AUTOSAR XML (schema 4-0-3)
package /ComponentTypes
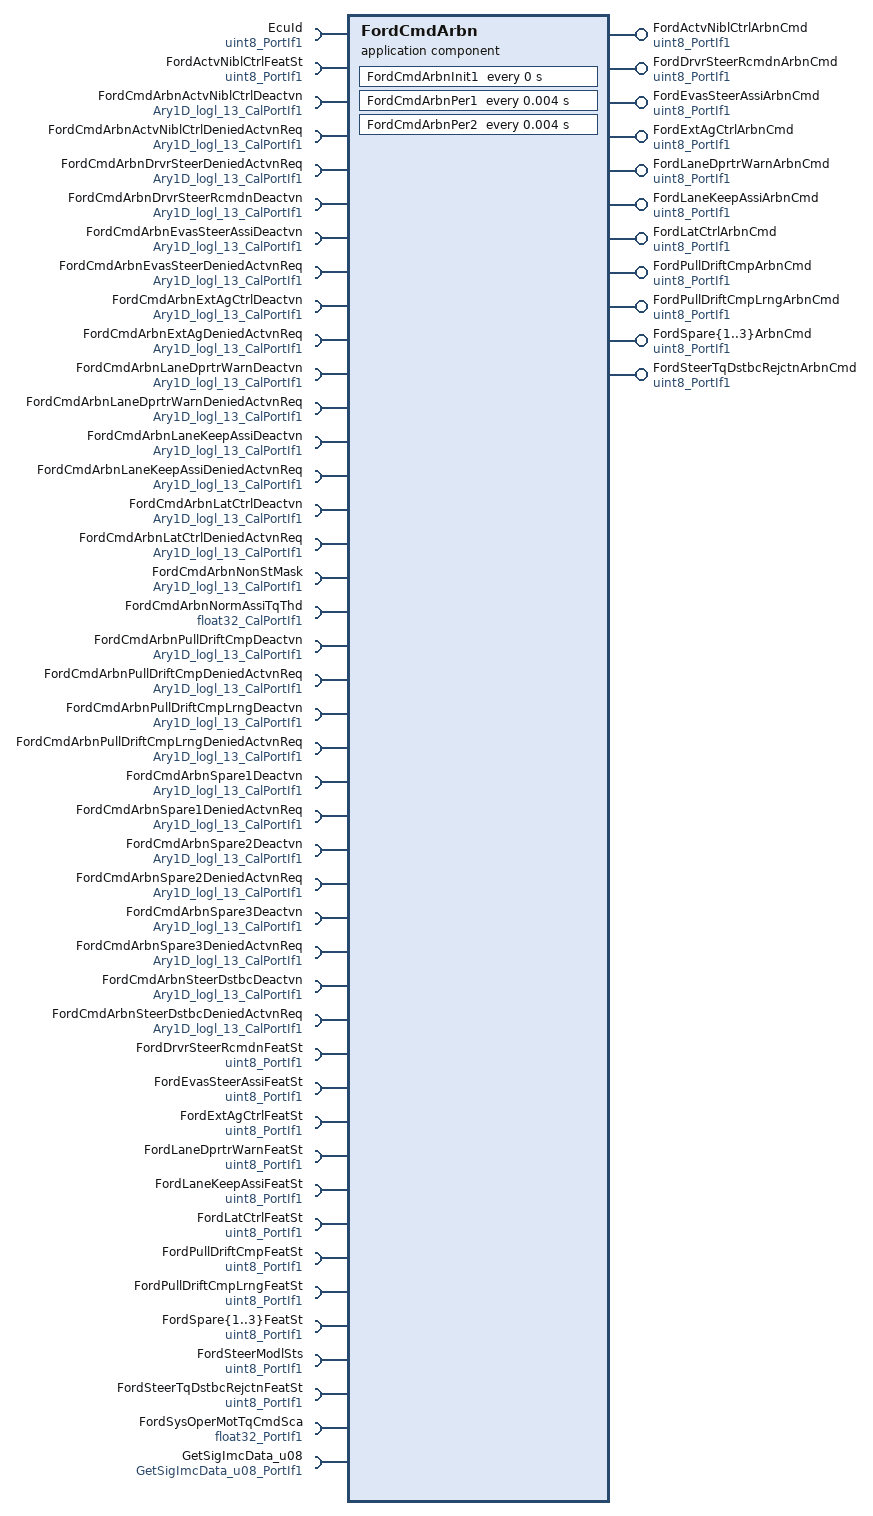
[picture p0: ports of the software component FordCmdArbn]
  application sw component type FordCmdArbn
    13 x provide port, all with nonqueued-sender-com-spec{data-element=Val, init-value=0}, provided-interface=uint8_PortIf1:
      FordActvNiblCtrlArbnCmd
      FordDrvrSteerRcmdnArbnCmd
      FordEvasSteerAssiArbnCmd
      FordExtAgCtrlArbnCmd
      FordLaneDprtrWarnArbnCmd
      FordLaneKeepAssiArbnCmd
      FordLatCtrlArbnCmd
      FordPullDriftCmpArbnCmd
      FordPullDriftCmpLrngArbnCmd
      FordSpare{1..3}ArbnCmd
      FordSteerTqDstbcRejctnArbnCmd
    45 x require port:
      EcuId: nonqueued-receiver-com-spec{data-element=Val, filter=data-filter-type=ALWAYS, init-value=0}, required-interface=uint8_PortIf1
      FordActvNiblCtrlFeatSt: nonqueued-receiver-com-spec{data-element=Val, filter=data-filter-type=ALWAYS, init-value=0}, required-interface=uint8_PortIf1
      FordCmdArbnActvNiblCtrlDeactvn: parameter-require-com-spec{init-value=[1, 1, 1, 1, 1, 1, 1, 1, 1, 0, 0, 0, 0], parameter=Ary1D}, required-interface=Ary1D_logl_13_CalPortIf1
      FordCmdArbnActvNiblCtrlDeniedActvnReq: parameter-require-com-spec{init-value=[1, 1, 1, 1, 1, 1, 1, 1, 1, 0, 0, 0, 0], parameter=Ary1D}, required-interface=Ary1D_logl_13_CalPortIf1
      FordCmdArbnDrvrSteerDeniedActvnReq: parameter-require-com-spec{init-value=[1, 1, 1, 1, 1, 1, 1, 1, 1, 0, 0, 0, 0], parameter=Ary1D}, required-interface=Ary1D_logl_13_CalPortIf1
      FordCmdArbnDrvrSteerRcmdnDeactvn: parameter-require-com-spec{init-value=[1, 1, 1, 1, 1, 1, 1, 1, 1, 0, 0, 0, 0], parameter=Ary1D}, required-interface=Ary1D_logl_13_CalPortIf1
      FordCmdArbnEvasSteerAssiDeactvn: parameter-require-com-spec{init-value=[1, 1, 1, 1, 1, 1, 1, 1, 1, 0, 0, 0, 0], parameter=Ary1D}, required-interface=Ary1D_logl_13_CalPortIf1
      FordCmdArbnEvasSteerDeniedActvnReq: parameter-require-com-spec{init-value=[1, 1, 1, 1, 1, 1, 1, 1, 1, 0, 0, 0, 0], parameter=Ary1D}, required-interface=Ary1D_logl_13_CalPortIf1
      FordCmdArbnExtAgCtrlDeactvn: parameter-require-com-spec{init-value=[1, 1, 1, 1, 1, 1, 1, 1, 1, 1, 0, 0, 0], parameter=Ary1D}, required-interface=Ary1D_logl_13_CalPortIf1
      FordCmdArbnExtAgDeniedActvnReq: parameter-require-com-spec{init-value=[1, 1, 1, 1, 1, 1, 1, 1, 1, 1, 0, 0, 0], parameter=Ary1D}, required-interface=Ary1D_logl_13_CalPortIf1
      FordCmdArbnLaneDprtrWarnDeactvn: parameter-require-com-spec{init-value=[1, 1, 1, 1, 1, 1, 1, 1, 1, 0, 0, 0, 0], parameter=Ary1D}, required-interface=Ary1D_logl_13_CalPortIf1
      FordCmdArbnLaneDprtrWarnDeniedActvnReq: parameter-require-com-spec{init-value=[1, 1, 1, 1, 1, 1, 1, 1, 1, 0, 0, 0, 0], parameter=Ary1D}, required-interface=Ary1D_logl_13_CalPortIf1
      FordCmdArbnLaneKeepAssiDeactvn: parameter-require-com-spec{init-value=[1, 1, 1, 1, 1, 1, 1, 1, 1, 0, 0, 0, 0], parameter=Ary1D}, required-interface=Ary1D_logl_13_CalPortIf1
      FordCmdArbnLaneKeepAssiDeniedActvnReq: parameter-require-com-spec{init-value=[1, 1, 1, 1, 1, 1, 1, 1, 1, 1, 0, 0, 0], parameter=Ary1D}, required-interface=Ary1D_logl_13_CalPortIf1
      FordCmdArbnLatCtrlDeactvn: parameter-require-com-spec{init-value=13 x 0, parameter=Ary1D}, required-interface=Ary1D_logl_13_CalPortIf1
      FordCmdArbnLatCtrlDeniedActvnReq: parameter-require-com-spec{init-value=13 x 0, parameter=Ary1D}, required-interface=Ary1D_logl_13_CalPortIf1
      FordCmdArbnNonStMask: parameter-require-com-spec{init-value=[1, 1, 1, 0, 1, 1, 0, 1, 1, 1, 0, 0, 0], parameter=Ary1D}, required-interface=Ary1D_logl_13_CalPortIf1
      FordCmdArbnNormAssiTqThd: parameter-require-com-spec{init-value=0, parameter=Val}, required-interface=float32_CalPortIf1
      FordCmdArbnPullDriftCmpDeactvn: parameter-require-com-spec{init-value=[1, 1, 1, 1, 1, 1, 1, 1, 1, 0, 0, 0, 0], parameter=Ary1D}, required-interface=Ary1D_logl_13_CalPortIf1
      FordCmdArbnPullDriftCmpDeniedActvnReq: parameter-require-com-spec{init-value=[1, 1, 1, 1, 1, 1, 1, 1, 1, 0, 0, 0, 0], parameter=Ary1D}, required-interface=Ary1D_logl_13_CalPortIf1
      FordCmdArbnPullDriftCmpLrngDeactvn: parameter-require-com-spec{init-value=[1, 1, 1, 1, 1, 1, 1, 1, 1, 0, 0, 0, 0], parameter=Ary1D}, required-interface=Ary1D_logl_13_CalPortIf1
      FordCmdArbnPullDriftCmpLrngDeniedActvnReq: parameter-require-com-spec{init-value=[1, 1, 1, 1, 1, 1, 1, 1, 1, 0, 0, 0, 0], parameter=Ary1D}, required-interface=Ary1D_logl_13_CalPortIf1
      FordCmdArbnSpare1Deactvn: parameter-require-com-spec{init-value=[1, 1, 1, 1, 1, 1, 1, 1, 1, 0, 0, 0, 0], parameter=Ary1D}, required-interface=Ary1D_logl_13_CalPortIf1
      FordCmdArbnSpare1DeniedActvnReq: parameter-require-com-spec{init-value=[1, 1, 1, 1, 1, 1, 1, 1, 1, 0, 0, 0, 0], parameter=Ary1D}, required-interface=Ary1D_logl_13_CalPortIf1
      FordCmdArbnSpare2Deactvn: parameter-require-com-spec{init-value=[1, 1, 1, 1, 1, 1, 1, 1, 1, 0, 0, 0, 0], parameter=Ary1D}, required-interface=Ary1D_logl_13_CalPortIf1
      FordCmdArbnSpare2DeniedActvnReq: parameter-require-com-spec{init-value=[1, 1, 1, 1, 1, 1, 1, 1, 1, 0, 0, 0, 0], parameter=Ary1D}, required-interface=Ary1D_logl_13_CalPortIf1
      FordCmdArbnSpare3Deactvn: parameter-require-com-spec{init-value=[1, 1, 1, 1, 1, 1, 1, 1, 1, 0, 0, 0, 0], parameter=Ary1D}, required-interface=Ary1D_logl_13_CalPortIf1
      FordCmdArbnSpare3DeniedActvnReq: parameter-require-com-spec{init-value=[1, 1, 1, 1, 1, 1, 1, 1, 1, 0, 0, 0, 0], parameter=Ary1D}, required-interface=Ary1D_logl_13_CalPortIf1
      FordCmdArbnSteerDstbcDeactvn: parameter-require-com-spec{init-value=13 x 0, parameter=Ary1D}, required-interface=Ary1D_logl_13_CalPortIf1
      FordCmdArbnSteerDstbcDeniedActvnReq: parameter-require-com-spec{init-value=13 x 0, parameter=Ary1D}, required-interface=Ary1D_logl_13_CalPortIf1
      FordDrvrSteerRcmdnFeatSt: nonqueued-receiver-com-spec{data-element=Val, filter=data-filter-type=ALWAYS, init-value=0}, required-interface=uint8_PortIf1
      FordEvasSteerAssiFeatSt: nonqueued-receiver-com-spec{data-element=Val, filter=data-filter-type=ALWAYS, init-value=0}, required-interface=uint8_PortIf1
      FordExtAgCtrlFeatSt: nonqueued-receiver-com-spec{data-element=Val, filter=data-filter-type=ALWAYS, init-value=0}, required-interface=uint8_PortIf1
      FordLaneDprtrWarnFeatSt: nonqueued-receiver-com-spec{data-element=Val, filter=data-filter-type=ALWAYS, init-value=0}, required-interface=uint8_PortIf1
      FordLaneKeepAssiFeatSt: nonqueued-receiver-com-spec{data-element=Val, filter=data-filter-type=ALWAYS, init-value=0}, required-interface=uint8_PortIf1
      FordLatCtrlFeatSt: nonqueued-receiver-com-spec{data-element=Val, filter=data-filter-type=ALWAYS, init-value=0}, required-interface=uint8_PortIf1
      FordPullDriftCmpFeatSt: nonqueued-receiver-com-spec{data-element=Val, filter=data-filter-type=ALWAYS, init-value=0}, required-interface=uint8_PortIf1
      FordPullDriftCmpLrngFeatSt: nonqueued-receiver-com-spec{data-element=Val, filter=data-filter-type=ALWAYS, init-value=0}, required-interface=uint8_PortIf1
      FordSpare{1..3}FeatSt: nonqueued-receiver-com-spec{data-element=Val, filter=data-filter-type=ALWAYS, init-value=0}, required-interface=uint8_PortIf1
      FordSteerModlSts: nonqueued-receiver-com-spec{data-element=Val, filter=data-filter-type=ALWAYS, init-value=0}, required-interface=uint8_PortIf1
      FordSteerTqDstbcRejctnFeatSt: nonqueued-receiver-com-spec{data-element=Val, filter=data-filter-type=ALWAYS, init-value=0}, required-interface=uint8_PortIf1
      FordSysOperMotTqCmdSca: nonqueued-receiver-com-spec{data-element=Val, filter=data-filter-type=ALWAYS, init-value=1}, required-interface=float32_PortIf1
      GetSigImcData_u08: required-interface=GetSigImcData_u08_PortIf1
    behavior FordCmdArbn_InternalBehavior
      timing event FordCmdArbn_InitEvent: start-on-event=FordCmdArbnInit1, period=0
      timing event TMT_FordCmdArbnPer1: start-on-event=FordCmdArbnPer1, period=0.004
      timing event TMT_FordCmdArbnPer2: start-on-event=FordCmdArbnPer2, period=0.004
      explicit-inter-runnable-variables:
        13 x data, all with type=uint8, init-value=0:
          FordActvNiblCtrlFeat
          FordDrvrSteerRcmdnFeat
          FordEvasSteerAssiFeat
          FordLaneDprtrWarnFeat
          FordLatCtrlFeat
          FordPullDriftCmpFeat
          FordPullDriftCmpLrngFeat
          FordSpare{1..3}Feat
          FordSteerTqDstbcRejctnFeat
          LaneKeepAssiFeat
          SteerSts
      port-api-options:
        enable-take-address=false, indirect-api=false, port=EcuId
        enable-take-address=false, indirect-api=false, port=FordActvNiblCtrlArbnCmd
        enable-take-address=false, indirect-api=false, port=FordActvNiblCtrlFeatSt
        enable-take-address=false, indirect-api=false, port=FordCmdArbnActvNiblCtrlDeactvn
        enable-take-address=false, indirect-api=false, port=FordCmdArbnActvNiblCtrlDeniedActvnReq
        enable-take-address=false, indirect-api=false, port=FordCmdArbnDrvrSteerDeniedActvnReq
        enable-take-address=false, indirect-api=false, port=FordCmdArbnDrvrSteerRcmdnDeactvn
        enable-take-address=false, indirect-api=false, port=FordCmdArbnEvasSteerAssiDeactvn
        enable-take-address=false, indirect-api=false, port=FordCmdArbnEvasSteerDeniedActvnReq
        enable-take-address=false, indirect-api=false, port=FordCmdArbnExtAgCtrlDeactvn
        enable-take-address=false, indirect-api=false, port=FordCmdArbnExtAgDeniedActvnReq
        enable-take-address=false, indirect-api=false, port=FordCmdArbnLaneDprtrWarnDeactvn
        enable-take-address=false, indirect-api=false, port=FordCmdArbnLaneDprtrWarnDeniedActvnReq
        enable-take-address=false, indirect-api=false, port=FordCmdArbnLaneKeepAssiDeactvn
        enable-take-address=false, indirect-api=false, port=FordCmdArbnLaneKeepAssiDeniedActvnReq
        enable-take-address=false, indirect-api=false, port=FordCmdArbnLatCtrlDeactvn
        enable-take-address=false, indirect-api=false, port=FordCmdArbnLatCtrlDeniedActvnReq
        enable-take-address=false, indirect-api=false, port=FordCmdArbnNonStMask
        enable-take-address=false, indirect-api=false, port=FordCmdArbnNormAssiTqThd
        enable-take-address=false, indirect-api=false, port=FordCmdArbnPullDriftCmpDeactvn
        enable-take-address=false, indirect-api=false, port=FordCmdArbnPullDriftCmpDeniedActvnReq
        enable-take-address=false, indirect-api=false, port=FordCmdArbnPullDriftCmpLrngDeactvn
        enable-take-address=false, indirect-api=false, port=FordCmdArbnPullDriftCmpLrngDeniedActvnReq
        enable-take-address=false, indirect-api=false, port=FordCmdArbnSpare1Deactvn
        enable-take-address=false, indirect-api=false, port=FordCmdArbnSpare1DeniedActvnReq
        enable-take-address=false, indirect-api=false, port=FordCmdArbnSpare2Deactvn
        enable-take-address=false, indirect-api=false, port=FordCmdArbnSpare2DeniedActvnReq
        enable-take-address=false, indirect-api=false, port=FordCmdArbnSpare3Deactvn
        enable-take-address=false, indirect-api=false, port=FordCmdArbnSpare3DeniedActvnReq
        enable-take-address=false, indirect-api=false, port=FordCmdArbnSteerDstbcDeactvn
        enable-take-address=false, indirect-api=false, port=FordCmdArbnSteerDstbcDeniedActvnReq
        enable-take-address=false, indirect-api=false, port=FordDrvrSteerRcmdnArbnCmd
        enable-take-address=false, indirect-api=false, port=FordDrvrSteerRcmdnFeatSt
        enable-take-address=false, indirect-api=false, port=FordEvasSteerAssiArbnCmd
        enable-take-address=false, indirect-api=false, port=FordEvasSteerAssiFeatSt
        enable-take-address=false, indirect-api=false, port=FordExtAgCtrlArbnCmd
        enable-take-address=false, indirect-api=false, port=FordExtAgCtrlFeatSt
        enable-take-address=false, indirect-api=false, port=FordLaneDprtrWarnArbnCmd
        enable-take-address=false, indirect-api=false, port=FordLaneDprtrWarnFeatSt
        enable-take-address=false, indirect-api=false, port=FordLaneKeepAssiArbnCmd
        enable-take-address=false, indirect-api=false, port=FordLaneKeepAssiFeatSt
        enable-take-address=false, indirect-api=false, port=FordLatCtrlArbnCmd
        enable-take-address=false, indirect-api=false, port=FordLatCtrlFeatSt
        enable-take-address=false, indirect-api=false, port=FordPullDriftCmpArbnCmd
        enable-take-address=false, indirect-api=false, port=FordPullDriftCmpFeatSt
        enable-take-address=false, indirect-api=false, port=FordPullDriftCmpLrngArbnCmd
        enable-take-address=false, indirect-api=false, port=FordPullDriftCmpLrngFeatSt
        enable-take-address=false, indirect-api=false, port=FordSpare1ArbnCmd
        enable-take-address=false, indirect-api=false, port=FordSpare1FeatSt
        enable-take-address=false, indirect-api=false, port=FordSpare2ArbnCmd
        enable-take-address=false, indirect-api=false, port=FordSpare2FeatSt
        enable-take-address=false, indirect-api=false, port=FordSpare3ArbnCmd
        enable-take-address=false, indirect-api=false, port=FordSpare3FeatSt
        enable-take-address=false, indirect-api=false, port=FordSteerModlSts
        enable-take-address=false, indirect-api=false, port=FordSteerTqDstbcRejctnArbnCmd
        enable-take-address=false, indirect-api=false, port=FordSteerTqDstbcRejctnFeatSt
        enable-take-address=false, indirect-api=false, port=FordSysOperMotTqCmdSca
        enable-take-address=false, indirect-api=false, port=GetSigImcData_u08
      runnable FordCmdArbnInit1
      runnable FordCmdArbnPer1
        data-receive-point-by-arguments:
          15 x access:
            REC_EcuId_Val: accessed-variable=EcuId.Val
            REC_FordActvNiblCtrlFeatSt_Val: accessed-variable=FordActvNiblCtrlFeatSt.Val
            REC_FordDrvrSteerRcmdnFeatSt_Val: accessed-variable=FordDrvrSteerRcmdnFeatSt.Val
            REC_FordEvasSteerAssiFeatSt_Val: accessed-variable=FordEvasSteerAssiFeatSt.Val
            REC_FordLaneDprtrWarnFeatSt_Val: accessed-variable=FordLaneDprtrWarnFeatSt.Val
            REC_FordLaneKeepAssiFeatSt_Val: accessed-variable=FordLaneKeepAssiFeatSt.Val
            REC_FordLatCtrlFeatSt_Val: accessed-variable=FordLatCtrlFeatSt.Val
            REC_FordPullDriftCmpFeatSt_Val: accessed-variable=FordPullDriftCmpFeatSt.Val
            REC_FordPullDriftCmpLrngFeatSt_Val: accessed-variable=FordPullDriftCmpLrngFeatSt.Val
            REC_FordSpare{1..3}FeatSt_Val: accessed-variable=FordSpare{1..3}FeatSt.Val
            REC_FordSteerModlSts_Val: accessed-variable=FordSteerModlSts.Val
            REC_FordSteerTqDstbcRejctnFeatSt_Val: accessed-variable=FordSteerTqDstbcRejctnFeatSt.Val
            REC_FordSysOperMotTqCmdSca_Val: accessed-variable=FordSysOperMotTqCmdSca.Val
        sync call SC_GetSigImcData_u08_Oper: operation=GetSigImcData_u08.Oper, timeout=0
        written-local-variables:
          13 x access:
            WRITE_FordActvNiblCtrlFeat: accessed-variable=FordActvNiblCtrlFeat
            WRITE_FordDrvrSteerRcmdnFeat: accessed-variable=FordDrvrSteerRcmdnFeat
            WRITE_FordEvasSteerAssiFeat: accessed-variable=FordEvasSteerAssiFeat
            WRITE_FordLaneDprtrWarnFeat: accessed-variable=FordLaneDprtrWarnFeat
            WRITE_FordLatCtrlFeat: accessed-variable=FordLatCtrlFeat
            WRITE_FordPullDriftCmpFeat: accessed-variable=FordPullDriftCmpFeat
            WRITE_FordPullDriftCmpLrngFeat: accessed-variable=FordPullDriftCmpLrngFeat
            WRITE_FordSpare{1..3}Feat: accessed-variable=FordSpare{1..3}Feat
            WRITE_FordSteerTqDstbcRejctnFeat: accessed-variable=FordSteerTqDstbcRejctnFeat
            WRITE_LaneKeepAssiFeat: accessed-variable=LaneKeepAssiFeat
            WRITE_SteerSts: accessed-variable=SteerSts
      runnable FordCmdArbnPer2
        data-receive-point-by-arguments:
          access REC_EcuId_Val: accessed-variable=EcuId.Val
          access REC_FordExtAgCtrlFeatSt_Val: accessed-variable=FordExtAgCtrlFeatSt.Val
        data-send-points:
          13 x access:
            SEND_FordActvNiblCtrlArbnCmd_Val: accessed-variable=FordActvNiblCtrlArbnCmd.Val
            SEND_FordDrvrSteerRcmdnArbnCmd_Val: accessed-variable=FordDrvrSteerRcmdnArbnCmd.Val
            SEND_FordEvasSteerAssiArbnCmd_Val: accessed-variable=FordEvasSteerAssiArbnCmd.Val
            SEND_FordExtAgCtrlArbnCmd_Val: accessed-variable=FordExtAgCtrlArbnCmd.Val
            SEND_FordLaneDprtrWarnArbnCmd_Val: accessed-variable=FordLaneDprtrWarnArbnCmd.Val
            SEND_FordLaneKeepAssiArbnCmd_Val: accessed-variable=FordLaneKeepAssiArbnCmd.Val
            SEND_FordLatCtrlArbnCmd_Val: accessed-variable=FordLatCtrlArbnCmd.Val
            SEND_FordPullDriftCmpArbnCmd_Val: accessed-variable=FordPullDriftCmpArbnCmd.Val
            SEND_FordPullDriftCmpLrngArbnCmd_Val: accessed-variable=FordPullDriftCmpLrngArbnCmd.Val
            SEND_FordSpare{1..3}ArbnCmd_Val: accessed-variable=FordSpare{1..3}ArbnCmd.Val
            SEND_FordSteerTqDstbcRejctnArbnCmd_Val: accessed-variable=FordSteerTqDstbcRejctnArbnCmd.Val
        read-local-variables:
          13 x access:
            READ_FordActvNiblCtrlFeat: accessed-variable=FordActvNiblCtrlFeat
            READ_FordDrvrSteerRcmdnFeat: accessed-variable=FordDrvrSteerRcmdnFeat
            READ_FordEvasSteerAssiFeat: accessed-variable=FordEvasSteerAssiFeat
            READ_FordLaneDprtrWarnFeat: accessed-variable=FordLaneDprtrWarnFeat
            READ_FordLatCtrlFeat: accessed-variable=FordLatCtrlFeat
            READ_FordPullDriftCmpFeat: accessed-variable=FordPullDriftCmpFeat
            READ_FordPullDriftCmpLrngFeat: accessed-variable=FordPullDriftCmpLrngFeat
            READ_FordSpare{1..3}Feat: accessed-variable=FordSpare{1..3}Feat
            READ_FordSteerTqDstbcRejctnFeat: accessed-variable=FordSteerTqDstbcRejctnFeat
            READ_LaneKeepAssiFeat: accessed-variable=LaneKeepAssiFeat
            READ_SteerSts: accessed-variable=SteerSts
  swc implementation FordCmdArbn_Implementation: behavior=FordCmdArbn_InternalBehavior
    code-descriptors:
      code Default: artifact-descriptors=autosar-engineering-object={short-label=Default, category=SWSRC}
